VERSION ""

NS_ :

BS_:

BU_: Pedals

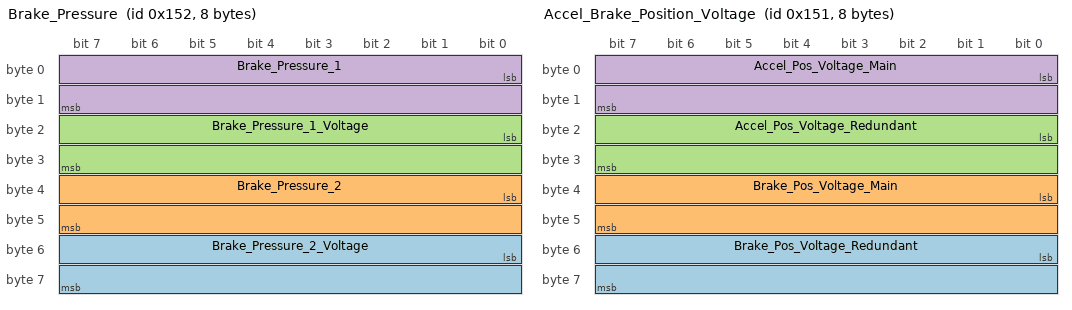
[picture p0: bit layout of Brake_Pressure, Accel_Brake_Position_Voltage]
BO_ 338 Brake_Pressure: 8 Pedals
 SG_ Brake_Pressure_2_Voltage : 48|16@1+ (0.001,0) [0|3.3] "V" Vector__XXX
 SG_ Brake_Pressure_2 : 32|16@1+ (0.1,0) [0|3000] "PSI" Vector__XXX
 SG_ Brake_Pressure_1_Voltage : 16|16@1+ (0.001,0) [0|3.3] "V" Vector__XXX
 SG_ Brake_Pressure_1 : 0|16@1+ (0.1,0) [0|3000] "PSI" Vector__XXX

BO_ 337 Accel_Brake_Position_Voltage: 8 Pedals
 SG_ Brake_Pos_Voltage_Redundant : 48|16@1+ (0.001,0) [0|3.3] "V" Vector__XXX
 SG_ Brake_Pos_Voltage_Main : 32|16@1+ (0.001,0) [0|3.3] "V" Vector__XXX
 SG_ Accel_Pos_Voltage_Redundant : 16|16@1+ (0.001,0) [0|3.3] "V" Vector__XXX
 SG_ Accel_Pos_Voltage_Main : 0|16@1+ (0.001,0) [0|3.3] "V" Vector__XXX

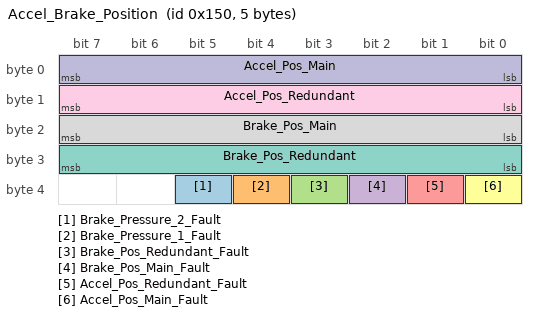
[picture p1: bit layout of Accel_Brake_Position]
BO_ 336 Accel_Brake_Position: 5 Pedals
 SG_ Brake_Pressure_2_Fault : 37|1@1+ (1,0) [0|0] "" Vector__XXX
 SG_ Brake_Pressure_1_Fault : 36|1@1+ (1,0) [0|0] "" Vector__XXX
 SG_ Brake_Pos_Redundant_Fault : 35|1@1+ (1,0) [0|0] "" Vector__XXX
 SG_ Brake_Pos_Main_Fault : 34|1@1+ (1,0) [0|0] "" Vector__XXX
 SG_ Accel_Pos_Redundant_Fault : 33|1@1+ (1,0) [0|0] "" Vector__XXX
 SG_ Accel_Pos_Main_Fault : 32|1@1+ (1,0) [0|0] "" Vector__XXX
 SG_ Brake_Pos_Redundant : 24|8@1+ (1,0) [0|100] "Percent" Vector__XXX
 SG_ Brake_Pos_Main : 16|8@1+ (1,0) [0|100] "Percent" Vector__XXX
 SG_ Accel_Pos_Redundant : 8|8@1+ (1,0) [0|100] "Percent" Vector__XXX
 SG_ Accel_Pos_Main : 0|8@1+ (1,0) [0|100] "Percent" Vector__XXX

CM_ SG_ 338 Brake_Pressure_2_Voltage "Brake Pressure Raw Voltage (Sensor 2)";
CM_ SG_ 338 Brake_Pressure_2 "Brake Pressure PSI (Sensor 2)";
CM_ SG_ 338 Brake_Pressure_1_Voltage "Brake Pressure Raw Voltage (Sensor 1)";
CM_ SG_ 338 Brake_Pressure_1 "Brake Pressure PSI (Sensor 1)";
CM_ SG_ 337 Brake_Pos_Voltage_Redundant "Brake Pedal Raw Voltage Measurement (Redundant Sensor)";
CM_ SG_ 337 Brake_Pos_Voltage_Main "Brake Pedal Raw Voltage Measurement (Main Sensor)";
CM_ SG_ 337 Accel_Pos_Voltage_Redundant "Accelerator Pedal Raw Voltage Measurement (Redundant Sensor)";
CM_ SG_ 337 Accel_Pos_Voltage_Main "Accelerator Pedal Raw Voltage Measurement (Main Sensor)";
CM_ SG_ 336 Brake_Pressure_2_Fault "Brake Pressure Sensor 2 Fault (0 normal, 1 fault)";
CM_ SG_ 336 Brake_Pressure_1_Fault "Brake Pressure Sensor 1 Fault (0 normal, 1 fault)";
CM_ SG_ 336 Brake_Pos_Redundant_Fault "Brake Pedal Redundant Sensor Fault (0 normal, 1 fault)";
CM_ SG_ 336 Brake_Pos_Main_Fault "Brake Pedal Main Sensor Fault (0 normal, 1 fault)";
CM_ SG_ 336 Accel_Pos_Redundant_Fault "Accelerator Pedal Redundant Sensor Fault (0 normal, 1 fault)";
CM_ SG_ 336 Accel_Pos_Main_Fault "Accelerator Pedal Main Sensor Fault (0 normal, 1 fault)";
CM_ SG_ 336 Brake_Pos_Redundant "Brake Pedal Position (Redundant Sensor)";
CM_ SG_ 336 Brake_Pos_Main "Brake Pedal Position (Main Sensor)";
CM_ SG_ 336 Accel_Pos_Redundant "Accelerator Pedal Position (Redundant Sensor)";
CM_ SG_ 336 Accel_Pos_Main "Accelerator Pedal Position (Main Sensor)";
BA_DEF_  "BusType" STRING ;
BA_DEF_ BO_  "VFrameFormat" ENUM  "StandardCAN","ExtendedCAN","reserved","J1939PG";
BA_DEF_DEF_  "BusType" "";
BA_DEF_DEF_  "VFrameFormat" "J1939PG";
BA_ "BusType" "CAN";
BA_ "VFrameFormat" BO_ 338 0;
BA_ "VFrameFormat" BO_ 337 0;
BA_ "VFrameFormat" BO_ 336 0;
